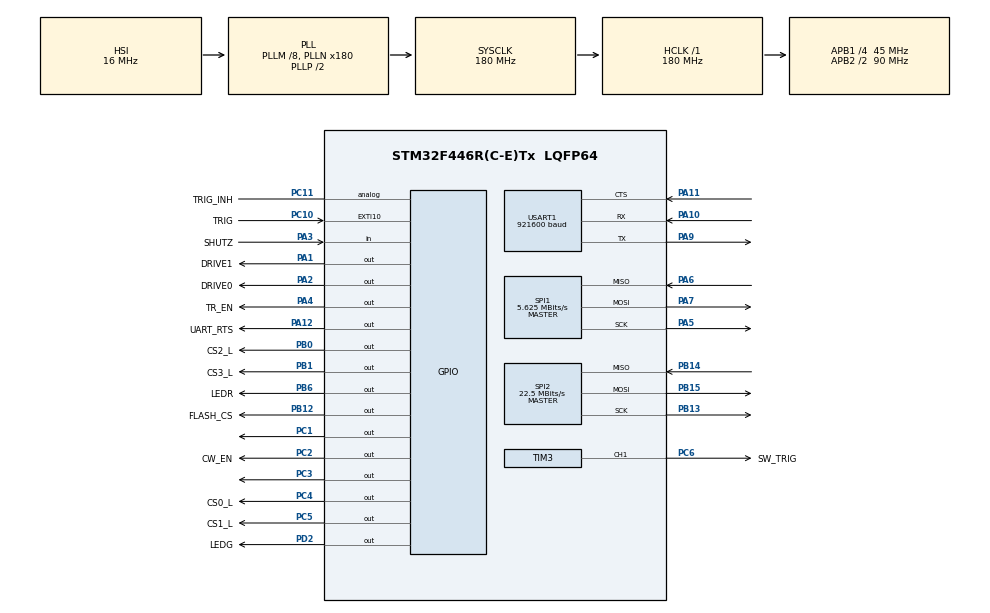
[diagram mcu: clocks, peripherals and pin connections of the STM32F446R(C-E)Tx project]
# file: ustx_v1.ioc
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Mcu.Family=STM32F4
Mcu.Name=STM32F446R(C-E)Tx
Mcu.Package=LQFP64
NVIC.EXTI15_10_IRQn=true\:0\:0\:false\:false\:true\:true\:true\:true
NVIC.PriorityGroup=NVIC_PRIORITYGROUP_4
NVIC.TIM1_UP_TIM10_IRQn=true\:0\:0\:false\:false\:true\:true\:true\:true
NVIC.USART1_IRQn=true\:0\:0\:false\:false\:true\:true\:true\:true
PA1.GPIO_Label=DRIVE1
PA1.Signal=GPIO_Output
PA10.Mode=Asynchronous
PA10.Signal=USART1_RX
PA11.Mode=CTS_Only
PA11.Signal=USART1_CTS
PA12.GPIO_Label=UART_RTS
PA12.Signal=GPIO_Output
PA2.GPIO_Label=DRIVE0
PA2.Signal=GPIO_Output
PA3.GPIO_Label=SHUTZ
PA3.GPIO_PuPd=GPIO_PULLUP
PA3.Signal=GPIO_Input
PA4.GPIO_Label=TR_EN
PA4.Signal=GPIO_Output
PA5.Mode=Full_Duplex_Master
PA5.Signal=SPI1_SCK
PA6.Mode=Full_Duplex_Master
PA6.Signal=SPI1_MISO
PA7.Mode=Full_Duplex_Master
PA7.Signal=SPI1_MOSI
PA9.Mode=Asynchronous
PA9.Signal=USART1_TX
PB0.GPIO_Label=CS2_L
PB0.Signal=GPIO_Output
PB1.GPIO_Label=CS3_L
PB1.Signal=GPIO_Output
PB12.GPIO_Label=FLASH_CS
PB12.Signal=GPIO_Output
PB13.Mode=Full_Duplex_Master
PB13.Signal=SPI2_SCK
PB14.Mode=Full_Duplex_Master
PB14.Signal=SPI2_MISO
PB15.Mode=Full_Duplex_Master
PB15.Signal=SPI2_MOSI
PB6.GPIO_Label=LEDR
PB6.GPIO_ModeDefaultOutputPP=GPIO_MODE_OUTPUT_OD
PB6.GPIO_Speed=GPIO_SPEED_FREQ_HIGH
PB6.PinState=GPIO_PIN_SET
PB6.Signal=GPIO_Output
PC1.Signal=GPIO_Output
PC10.GPIO_Label=TRIG
PC10.GPIO_ModeDefaultEXTI=GPIO_MODE_IT_FALLING
PC10.Signal=GPXTI10
PC11.GPIO_Label=TRIG_INH
PC11.Signal=GPIO_Analog
PC2.GPIO_Label=CW_EN
PC2.Signal=GPIO_Output
PC3.Signal=GPIO_Output
PC4.GPIO_Label=CS0_L
PC4.Signal=GPIO_Output
PC5.GPIO_Label=CS1_L
PC5.Signal=GPIO_Output
PC6.GPIO_Label=SW_TRIG
PC6.Signal=S_TIM3_CH1
PD2.GPIO_Label=LEDG
PD2.GPIO_ModeDefaultOutputPP=GPIO_MODE_OUTPUT_OD
PD2.GPIO_Speed=GPIO_SPEED_FREQ_HIGH
PD2.PinState=GPIO_PIN_SET
PD2.Signal=GPIO_Output
ProjectManager.HeapSize=0x200
ProjectManager.StackSize=0x400
ProjectManager.TargetToolchain=STM32CubeIDE
RCC.AHBFreq_Value=180000000
RCC.APB1CLKDivider=RCC_HCLK_DIV4
RCC.APB1Freq_Value=45000000
RCC.APB1TimFreq_Value=90000000
RCC.APB2CLKDivider=RCC_HCLK_DIV2
RCC.APB2Freq_Value=90000000
RCC.APB2TimFreq_Value=180000000
RCC.CortexFreq_Value=180000000
RCC.HCLKFreq_Value=180000000
RCC.PLLM=8
RCC.PLLN=180
RCC.SYSCLKFreq_VALUE=180000000
RCC.SYSCLKSource=RCC_SYSCLKSOURCE_PLLCLK
RCC.USBFreq_Value=180000000
RCC.VCOOutputFreq_Value=360000000
SH.S_TIM3_CH1.0=TIM3_CH1,PWM Generation1 CH1
SPI1.BaudRatePrescaler=SPI_BAUDRATEPRESCALER_16
SPI1.CalculateBaudRate=5.625 MBits/s
SPI1.Direction=SPI_DIRECTION_2LINES
SPI1.Mode=SPI_MODE_MASTER
SPI1.VirtualType=VM_MASTER
SPI2.BaudRatePrescaler=SPI_BAUDRATEPRESCALER_2
SPI2.CalculateBaudRate=22.5 MBits/s
SPI2.Direction=SPI_DIRECTION_2LINES
SPI2.Mode=SPI_MODE_MASTER
SPI2.VirtualType=VM_MASTER
TIM1.AutoReloadPreload=TIM_AUTORELOAD_PRELOAD_ENABLE
TIM1.Period=0xec77
TIM1.TIM_MasterOutputTrigger=TIM_TRGO_RESET
TIM3.AutoReloadPreload=TIM_AUTORELOAD_PRELOAD_ENABLE
TIM3.Channel-PWM\ Generation1\ CH1=TIM_CHANNEL_1
TIM3.Period=4999
TIM3.Prescaler=359
TIM3.Pulse-PWM\ Generation1\ CH1=1999
USART1.BaudRate=921600
USART1.VirtualMode=VM_ASYNC
VP_TIM1_VS_ClockSourceINT.Mode=Internal
VP_TIM1_VS_OPM.Mode=OPM_bit
VP_TIM3_VS_ClockSourceINT.Mode=Internal
board=custom

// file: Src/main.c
/* USER CODE BEGIN Header */
/**
  ******************************************************************************
  * @file           : main.c
  * @brief          : Main program body
  ******************************************************************************
  * @attention
  *
  * <h2><center>&copy; Copyright (c) 2019 STMicroelectronics.
  * All rights reserved.</center></h2>
  *
  * This software component is licensed by ST under BSD 3-Clause license,
  * the "License"; You may not use this file except in compliance with the
  * License. You may obtain a copy of the License at:
  *                        opensource.org/licenses/BSD-3-Clause
  *
  ******************************************************************************
  */
/* USER CODE END Header */
#include "main.h"

/* USER CODE BEGIN Includes */
#include "maincc.h"

/* USER CODE END Includes */

SPI_HandleTypeDef hspi1;
SPI_HandleTypeDef hspi2;

TIM_HandleTypeDef htim1;
TIM_HandleTypeDef htim3;

UART_HandleTypeDef huart1;

void SystemClock_Config(void);
static void MX_GPIO_Init(void);
static void MX_SPI1_Init(void);
static void MX_USART1_UART_Init(void);
static void MX_SPI2_Init(void);
static void MX_TIM1_Init(void);
static void MX_TIM3_Init(void);

int main(void)
{

  /* USER CODE BEGIN 1 */
  GPIO_InitTypeDef GPIO_InitStruct = {0};

  /* USER CODE END 1 */

  /* MCU Configuration--------------------------------------------------------*/

  /* Reset of all peripherals, Initializes the Flash interface and the Systick. */
  HAL_Init();

  /* Configure the system clock */
  SystemClock_Config();

  /* Initialize all configured peripherals */
  MX_GPIO_Init();
  MX_SPI1_Init();
  MX_USART1_UART_Init();
  MX_SPI2_Init();
  MX_TIM1_Init();
  MX_TIM3_Init();
  /* USER CODE BEGIN 2 */
  // configure inhibit

  GPIO_InitStruct.Pin = GPIO_PIN_11; // PC11
  GPIO_InitStruct.Mode = GPIO_MODE_OUTPUT_PP; // Output Push Pull Mode
  GPIO_InitStruct.Pull = GPIO_NOPULL;
  GPIO_InitStruct.Speed = GPIO_SPEED_FREQ_LOW;
  HAL_GPIO_Init(GPIOC, &GPIO_InitStruct); // Initialize PC11
  HAL_Delay(10);
  HAL_GPIO_WritePin(GPIOC, GPIO_PIN_11, GPIO_PIN_RESET); // Set PC11 High
  HAL_Delay(10);

  HAL_TIM_PWM_Start(&htim3, TIM_CHANNEL_1);

  MainCC();
  /* USER CODE END 2 */

  /* Infinite loop */
  while (1)
  {

  }
}

void SystemClock_Config(void)
{
  RCC_OscInitTypeDef RCC_OscInitStruct = {0};
  RCC_ClkInitTypeDef RCC_ClkInitStruct = {0};

  /** Configure the main internal regulator output voltage
  */
  __HAL_RCC_PWR_CLK_ENABLE();
  __HAL_PWR_VOLTAGESCALING_CONFIG(PWR_REGULATOR_VOLTAGE_SCALE1);

  /** Initializes the RCC Oscillators according to the specified parameters
  * in the RCC_OscInitTypeDef structure.
  */
  RCC_OscInitStruct.OscillatorType = RCC_OSCILLATORTYPE_HSI;
  RCC_OscInitStruct.HSIState = RCC_HSI_ON;
  RCC_OscInitStruct.HSICalibrationValue = RCC_HSICALIBRATION_DEFAULT;
  RCC_OscInitStruct.PLL.PLLState = RCC_PLL_ON;
  RCC_OscInitStruct.PLL.PLLSource = RCC_PLLSOURCE_HSI;
  RCC_OscInitStruct.PLL.PLLM = 8;
  RCC_OscInitStruct.PLL.PLLN = 180;
  RCC_OscInitStruct.PLL.PLLP = RCC_PLLP_DIV2;
  RCC_OscInitStruct.PLL.PLLQ = 2;
  RCC_OscInitStruct.PLL.PLLR = 2;
  if (HAL_RCC_OscConfig(&RCC_OscInitStruct) != HAL_OK)
  {
    Error_Handler();
  }

  /** Activate the Over-Drive mode
  */
  if (HAL_PWREx_EnableOverDrive() != HAL_OK)
  {
    Error_Handler();
  }

  /** Initializes the CPU, AHB and APB buses clocks
  */
  RCC_ClkInitStruct.ClockType = RCC_CLOCKTYPE_HCLK|RCC_CLOCKTYPE_SYSCLK
                              |RCC_CLOCKTYPE_PCLK1|RCC_CLOCKTYPE_PCLK2;
  RCC_ClkInitStruct.SYSCLKSource = RCC_SYSCLKSOURCE_PLLCLK;
  RCC_ClkInitStruct.AHBCLKDivider = RCC_SYSCLK_DIV1;
  RCC_ClkInitStruct.APB1CLKDivider = RCC_HCLK_DIV4;
  RCC_ClkInitStruct.APB2CLKDivider = RCC_HCLK_DIV2;

  if (HAL_RCC_ClockConfig(&RCC_ClkInitStruct, FLASH_LATENCY_5) != HAL_OK)
  {
    Error_Handler();
  }
}

static void MX_SPI1_Init(void)
{

  /* SPI1 parameter configuration*/
  hspi1.Instance = SPI1;
  hspi1.Init.Mode = SPI_MODE_MASTER;
  hspi1.Init.Direction = SPI_DIRECTION_2LINES;
  hspi1.Init.DataSize = SPI_DATASIZE_8BIT;
  hspi1.Init.CLKPolarity = SPI_POLARITY_LOW;
  hspi1.Init.CLKPhase = SPI_PHASE_1EDGE;
  hspi1.Init.NSS = SPI_NSS_SOFT;
  hspi1.Init.BaudRatePrescaler = SPI_BAUDRATEPRESCALER_16;
  hspi1.Init.FirstBit = SPI_FIRSTBIT_MSB;
  hspi1.Init.TIMode = SPI_TIMODE_DISABLE;
  hspi1.Init.CRCCalculation = SPI_CRCCALCULATION_DISABLE;
  hspi1.Init.CRCPolynomial = 10;
  if (HAL_SPI_Init(&hspi1) != HAL_OK)
  {
    Error_Handler();
  }

}

static void MX_SPI2_Init(void)
{

  /* SPI2 parameter configuration*/
  hspi2.Instance = SPI2;
  hspi2.Init.Mode = SPI_MODE_MASTER;
  hspi2.Init.Direction = SPI_DIRECTION_2LINES;
  hspi2.Init.DataSize = SPI_DATASIZE_8BIT;
  hspi2.Init.CLKPolarity = SPI_POLARITY_LOW;
  hspi2.Init.CLKPhase = SPI_PHASE_1EDGE;
  hspi2.Init.NSS = SPI_NSS_SOFT;
  hspi2.Init.BaudRatePrescaler = SPI_BAUDRATEPRESCALER_2;
  hspi2.Init.FirstBit = SPI_FIRSTBIT_MSB;
  hspi2.Init.TIMode = SPI_TIMODE_DISABLE;
  hspi2.Init.CRCCalculation = SPI_CRCCALCULATION_DISABLE;
  hspi2.Init.CRCPolynomial = 10;
  if (HAL_SPI_Init(&hspi2) != HAL_OK)
  {
    Error_Handler();
  }

}

static void MX_TIM1_Init(void)
{

  TIM_ClockConfigTypeDef sClockSourceConfig = {0};
  TIM_MasterConfigTypeDef sMasterConfig = {0};

  htim1.Instance = TIM1;
  htim1.Init.Prescaler = 0;
  htim1.Init.CounterMode = TIM_COUNTERMODE_UP;
  htim1.Init.Period = 0xec77;
  htim1.Init.ClockDivision = TIM_CLOCKDIVISION_DIV1;
  htim1.Init.RepetitionCounter = 0;
  htim1.Init.AutoReloadPreload = TIM_AUTORELOAD_PRELOAD_ENABLE;
  if (HAL_TIM_Base_Init(&htim1) != HAL_OK)
  {
    Error_Handler();
  }
  sClockSourceConfig.ClockSource = TIM_CLOCKSOURCE_INTERNAL;
  if (HAL_TIM_ConfigClockSource(&htim1, &sClockSourceConfig) != HAL_OK)
  {
    Error_Handler();
  }
  if (HAL_TIM_OnePulse_Init(&htim1, TIM_OPMODE_SINGLE) != HAL_OK)
  {
    Error_Handler();
  }
  sMasterConfig.MasterOutputTrigger = TIM_TRGO_RESET;
  sMasterConfig.MasterSlaveMode = TIM_MASTERSLAVEMODE_DISABLE;
  if (HAL_TIMEx_MasterConfigSynchronization(&htim1, &sMasterConfig) != HAL_OK)
  {
    Error_Handler();
  }
  /* USER CODE BEGIN TIM1_Init 2 */
  // flag is set by init
  __HAL_TIM_CLEAR_FLAG(&htim1, TIM_FLAG_UPDATE);
  /* USER CODE END TIM1_Init 2 */

}

static void MX_TIM3_Init(void)
{

  TIM_ClockConfigTypeDef sClockSourceConfig = {0};
  TIM_MasterConfigTypeDef sMasterConfig = {0};
  TIM_OC_InitTypeDef sConfigOC = {0};

  htim3.Instance = TIM3;
  htim3.Init.Prescaler = 359;
  htim3.Init.CounterMode = TIM_COUNTERMODE_UP;
  htim3.Init.Period = 4999;
  htim3.Init.ClockDivision = TIM_CLOCKDIVISION_DIV1;
  htim3.Init.AutoReloadPreload = TIM_AUTORELOAD_PRELOAD_ENABLE;
  if (HAL_TIM_Base_Init(&htim3) != HAL_OK)
  {
    Error_Handler();
  }
  sClockSourceConfig.ClockSource = TIM_CLOCKSOURCE_INTERNAL;
  if (HAL_TIM_ConfigClockSource(&htim3, &sClockSourceConfig) != HAL_OK)
  {
    Error_Handler();
  }
  if (HAL_TIM_PWM_Init(&htim3) != HAL_OK)
  {
    Error_Handler();
  }
  sMasterConfig.MasterOutputTrigger = TIM_TRGO_RESET;
  sMasterConfig.MasterSlaveMode = TIM_MASTERSLAVEMODE_DISABLE;
  if (HAL_TIMEx_MasterConfigSynchronization(&htim3, &sMasterConfig) != HAL_OK)
  {
    Error_Handler();
  }
  sConfigOC.OCMode = TIM_OCMODE_PWM1;
  sConfigOC.Pulse = 1999;
  sConfigOC.OCPolarity = TIM_OCPOLARITY_HIGH;
  sConfigOC.OCFastMode = TIM_OCFAST_DISABLE;
  if (HAL_TIM_PWM_ConfigChannel(&htim3, &sConfigOC, TIM_CHANNEL_1) != HAL_OK)
  {
    Error_Handler();
  }
  HAL_TIM_MspPostInit(&htim3);

}

static void MX_USART1_UART_Init(void)
{

  huart1.Instance = USART1;
  huart1.Init.BaudRate = 921600;
  huart1.Init.WordLength = UART_WORDLENGTH_8B;
  huart1.Init.StopBits = UART_STOPBITS_1;
  huart1.Init.Parity = UART_PARITY_NONE;
  huart1.Init.Mode = UART_MODE_TX_RX;
  huart1.Init.HwFlowCtl = UART_HWCONTROL_CTS;
  huart1.Init.OverSampling = UART_OVERSAMPLING_16;
  if (HAL_UART_Init(&huart1) != HAL_OK)
  {
    Error_Handler();
  }

}

static void MX_GPIO_Init(void)
{
  GPIO_InitTypeDef GPIO_InitStruct = {0};

  /* GPIO Ports Clock Enable */
  __HAL_RCC_GPIOC_CLK_ENABLE();
  __HAL_RCC_GPIOA_CLK_ENABLE();
  __HAL_RCC_GPIOB_CLK_ENABLE();
  __HAL_RCC_GPIOD_CLK_ENABLE();

  /*Configure GPIO pin Output Level */
  HAL_GPIO_WritePin(GPIOC, GPIO_PIN_1|CW_EN_Pin|GPIO_PIN_3|CS0_L_Pin
                          |CS1_L_Pin, GPIO_PIN_RESET);

  /*Configure GPIO pin Output Level */
  HAL_GPIO_WritePin(GPIOA, DRIVE1_Pin|DRIVE0_Pin|TR_EN_Pin|UART_RTS_Pin, GPIO_PIN_RESET);

  /*Configure GPIO pin Output Level */
  HAL_GPIO_WritePin(GPIOB, CS2_L_Pin|CS3_L_Pin|FLASH_CS_Pin, GPIO_PIN_RESET);

  /*Configure GPIO pin Output Level */
  HAL_GPIO_WritePin(LEDG_GPIO_Port, LEDG_Pin, GPIO_PIN_SET);

  /*Configure GPIO pin Output Level */
  HAL_GPIO_WritePin(LEDR_GPIO_Port, LEDR_Pin, GPIO_PIN_SET);

  /*Configure GPIO pins : PC1 CW_EN_Pin PC3 CS0_L_Pin
                           CS1_L_Pin */
  GPIO_InitStruct.Pin = GPIO_PIN_1|CW_EN_Pin|GPIO_PIN_3|CS0_L_Pin
                          |CS1_L_Pin;
  GPIO_InitStruct.Mode = GPIO_MODE_OUTPUT_PP;
  GPIO_InitStruct.Pull = GPIO_NOPULL;
  GPIO_InitStruct.Speed = GPIO_SPEED_FREQ_LOW;
  HAL_GPIO_Init(GPIOC, &GPIO_InitStruct);

  /*Configure GPIO pins : DRIVE1_Pin DRIVE0_Pin TR_EN_Pin UART_RTS_Pin */
  GPIO_InitStruct.Pin = DRIVE1_Pin|DRIVE0_Pin|TR_EN_Pin|UART_RTS_Pin;
  GPIO_InitStruct.Mode = GPIO_MODE_OUTPUT_PP;
  GPIO_InitStruct.Pull = GPIO_NOPULL;
  GPIO_InitStruct.Speed = GPIO_SPEED_FREQ_LOW;
  HAL_GPIO_Init(GPIOA, &GPIO_InitStruct);

  /*Configure GPIO pin : SHUTZ_Pin */
  GPIO_InitStruct.Pin = SHUTZ_Pin;
  GPIO_InitStruct.Mode = GPIO_MODE_INPUT;
  GPIO_InitStruct.Pull = GPIO_PULLUP;
  HAL_GPIO_Init(SHUTZ_GPIO_Port, &GPIO_InitStruct);

  /*Configure GPIO pins : CS2_L_Pin CS3_L_Pin FLASH_CS_Pin */
  GPIO_InitStruct.Pin = CS2_L_Pin|CS3_L_Pin|FLASH_CS_Pin;
  GPIO_InitStruct.Mode = GPIO_MODE_OUTPUT_PP;
  GPIO_InitStruct.Pull = GPIO_NOPULL;
  GPIO_InitStruct.Speed = GPIO_SPEED_FREQ_LOW;
  HAL_GPIO_Init(GPIOB, &GPIO_InitStruct);

  /*Configure GPIO pin : TRIG_Pin */
  GPIO_InitStruct.Pin = TRIG_Pin;
  GPIO_InitStruct.Mode = GPIO_MODE_IT_FALLING;
  GPIO_InitStruct.Pull = GPIO_NOPULL;
  HAL_GPIO_Init(TRIG_GPIO_Port, &GPIO_InitStruct);

  /*Configure GPIO pin : TRIG_INH_Pin */
  GPIO_InitStruct.Pin = TRIG_INH_Pin;
  GPIO_InitStruct.Mode = GPIO_MODE_ANALOG;
  GPIO_InitStruct.Pull = GPIO_NOPULL;
  HAL_GPIO_Init(TRIG_INH_GPIO_Port, &GPIO_InitStruct);

  /*Configure GPIO pin : LEDG_Pin */
  GPIO_InitStruct.Pin = LEDG_Pin;
  GPIO_InitStruct.Mode = GPIO_MODE_OUTPUT_OD;
  GPIO_InitStruct.Pull = GPIO_NOPULL;
  GPIO_InitStruct.Speed = GPIO_SPEED_FREQ_HIGH;
  HAL_GPIO_Init(LEDG_GPIO_Port, &GPIO_InitStruct);

  /*Configure GPIO pin : LEDR_Pin */
  GPIO_InitStruct.Pin = LEDR_Pin;
  GPIO_InitStruct.Mode = GPIO_MODE_OUTPUT_OD;
  GPIO_InitStruct.Pull = GPIO_NOPULL;
  GPIO_InitStruct.Speed = GPIO_SPEED_FREQ_HIGH;
  HAL_GPIO_Init(LEDR_GPIO_Port, &GPIO_InitStruct);

  /* EXTI interrupt init*/
  HAL_NVIC_SetPriority(EXTI15_10_IRQn, 0, 0);
  HAL_NVIC_EnableIRQ(EXTI15_10_IRQn);

}

void Error_Handler(void)
{
}
